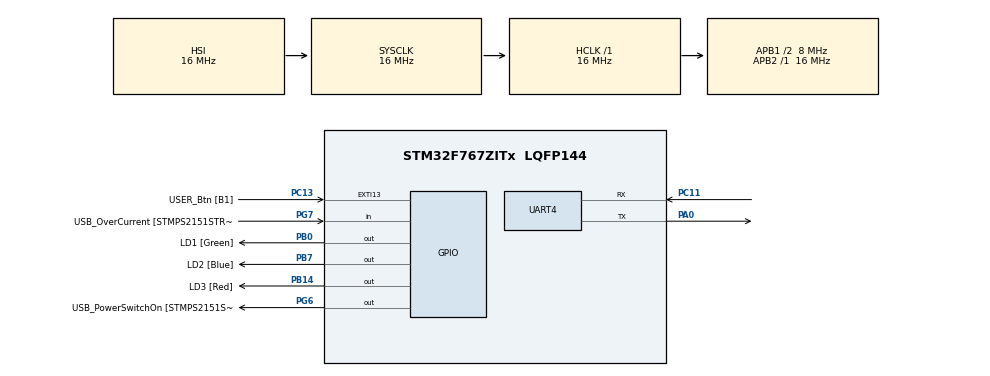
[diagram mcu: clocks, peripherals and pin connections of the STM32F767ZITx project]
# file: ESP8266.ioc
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Mcu.Family=STM32F7
RCC.CortexFreq_Value=16000000
PG6.Signal=GPIO_Output
PB14.GPIO_Label=LD3 [Red]
PG6.GPIO_Label=USB_PowerSwitchOn [STMPS2151STR_EN]
PA14.GPIO_Label=TCK
RCC.SYSCLKSourceVirtual=RCC_SYSCLKSOURCE_PLLCLK
PA0/WKUP.Signal=UART4_TX
PB0.GPIO_Label=LD1 [Green]
PC13.GPIO_Label=USER_Btn [B1]
PB13.GPIO_Label=RMII_TXD1 [LAN8742A-CZ-TR_TXD1]
PB13.Signal=ETH_TXD1
PG13.Signal=ETH_TXD0
PG11.Signal=ETH_TX_EN
ProjectManager.StackSize=0x400
PA12.Signal=USB_OTG_FS_DP
RCC.HCLKFreq_Value=16000000
RCC.APB2TimFreq_Value=16000000
PH1/OSC_OUT.Signal=RCC_OSC_OUT
PD8.Signal=USART3_TX
RCC.AHBFreq_Value=16000000
RCC.HSE_VALUE=16000000
TIM14.Period=20001
RCC.PLLMUL=RCC_PLL_MUL9
PC4.GPIO_Label=RMII_RXD0 [LAN8742A-CZ-TR_RXD0]
PA10.GPIO_Label=USB_ID
PB7.Signal=GPIO_Output
PA8.Signal=USB_OTG_FS_SOF
PB7.GPIO_Label=LD2 [Blue]
Mcu.Package=LQFP144
PC14/OSC32_IN.Signal=RCC_OSC32_IN
PA2.GPIO_Label=RMII_MDIO [LAN8742A-CZ-TR_MDIO]
PA10.Signal=USB_OTG_FS_ID
PC11.Mode=Asynchronous
RCC.APB1TimFreq_Value=16000000
PG11.GPIO_Label=RMII_TX_EN [LAN8742A-CZ-TR_TXEN]
PC5.Signal=ETH_RXD1
VP_TIM14_VS_ClockSourceINT.Mode=Enable_Timer
NVIC.UART4_IRQn=true\:0\:0\:false\:false\:true\:true\:true
PB3.GPIO_Label=SW0
PG7.Signal=GPIO_Input
PD9.GPIO_Label=STLK_TX [STM32F103CBT6_PA2]
PC13.Signal=GPXTI13
PA9.GPIO_Label=USB_VBUS
PC11.Signal=UART4_RX
PC4.Signal=ETH_RXD0
PA11.GPIO_Label=USB_DM
PD9.Signal=USART3_RX
RCC.APB1CLKDivider=RCC_HCLK_DIV2
PG13.GPIO_Label=RMII_TXD0 [LAN8742A-CZ-TR_TXD0]
PA12.GPIO_Label=USB_DP
PD8.GPIO_Label=STLK_RX [STM32F103CBT6_PA3]
PA13.Signal=SYS_JTMS-SWDIO
PA8.GPIO_Label=USB_SOF [TP1]
ProjectManager.TargetToolchain=STM32CubeIDE
PA9.Signal=USB_OTG_FS_VBUS
RCC.USBFreq_Value=96000000
RCC.LSE_VALUE=32768
PA1.Signal=ETH_REF_CLK
PA0/WKUP.Mode=Asynchronous
PB14.Signal=GPIO_Output
board=NUCLEO-F767ZI
RCC.VCOOutputFreq_Value=192000000
PH0/OSC_IN.Signal=RCC_OSC_IN
RCC.APB2Freq_Value=16000000
RCC.PRESCALERUSB=RCC_USBCLKSOURCE_PLL_DIV1_5
PG7.GPIO_Label=USB_OverCurrent [STMPS2151STR_FAULT]
PA1.GPIO_Label=RMII_REF_CLK [LAN8742A-CZ-TR_REFCLK0]
PC1.GPIO_Label=RMII_MDC [LAN8742A-CZ-TR_MDC]
Mcu.Name=STM32F767ZITx
TIM14.Prescaler=1601-1
PA2.Signal=ETH_MDIO
PA13.GPIO_Label=TMS
RCC.48MHZClocksFreq_Value=24000000
PB3.Signal=SYS_JTDO-SWO
RCC.SYSCLKFreq_VALUE=16000000
PA7.GPIO_Label=RMII_CRS_DV [LAN8742A-CZ-TR_CRS_DV]
PC5.GPIO_Label=RMII_RXD1 [LAN8742A-CZ-TR_RXD1]
PA11.Signal=USB_OTG_FS_DM
PA14.Signal=SYS_JTCK-SWCLK
ProjectManager.HeapSize=0x200
RCC.HSI_VALUE=16000000
PH0/OSC_IN.GPIO_Label=MCO [STM32F103CBT6_PA8]
NVIC.PriorityGroup=NVIC_PRIORITYGROUP_4
PC15/OSC32_OUT.Signal=RCC_OSC32_OUT
RCC.APB1Freq_Value=8000000
PB0.Signal=GPIO_Output
PC1.Signal=ETH_MDC
PA7.Signal=ETH_CRS_DV

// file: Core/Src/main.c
/* USER CODE BEGIN Header */
/**
  ******************************************************************************
  * @file           : main.c
  * @brief          : Main program body
  ******************************************************************************
  * @attention
  *
  * <h2><center>&copy; Copyright (c) 2021 STMicroelectronics.
  * All rights reserved.</center></h2>
  *
  * This software component is licensed by ST under BSD 3-Clause license,
  * the "License"; You may not use this file except in compliance with the
  * License. You may obtain a copy of the License at:
  *                        opensource.org/licenses/BSD-3-Clause
  *
  ******************************************************************************
  */
/* USER CODE END Header */
#include "main.h"

/* USER CODE BEGIN Includes */
#include "ESP8266.h"
/* USER CODE END Includes */

TIM_HandleTypeDef htim14;

UART_HandleTypeDef huart4;

/* USER CODE BEGIN PV */
char SSID[20] = "\"SSID\"";
char password[20] = "\"Password\"";
char IP[20] = "\"184.106.153.149\"";
char write_API_key[17] = "ZU5WVONXNXJPLRUX";
const int port = 80;

double sensor_output = 60.23;
bool OK_received_flag;

struct ESP8266 ESP = {SSID, password, IP, port, write_API_key};

/* USER CODE END PV */

void SystemClock_Config(void);
static void MX_GPIO_Init(void);
static void MX_UART4_Init(void);
static void MX_TIM14_Init(void);

int main(void)
{

  /* MCU Configuration--------------------------------------------------------*/

  /* Reset of all peripherals, Initializes the Flash interface and the Systick. */
  HAL_Init();

  /* Configure the system clock */
  SystemClock_Config();

  /* Initialize all configured peripherals */
  MX_GPIO_Init();
  MX_UART4_Init();
  MX_TIM14_Init();
  /* USER CODE BEGIN 2 */

  OK_received_flag = ESP8266_Test();
  ESP8266_WiFiSetup(ESP.SSID, ESP.password);
  TCP_Connect(ESP.IP, ESP.port);
  TS_Write(ESP.write_API_key, sensor_output);
  /* USER CODE END 2 */

  /* Infinite loop */
  while (1)
  {

  }
}

void SystemClock_Config(void)
{
  RCC_OscInitTypeDef RCC_OscInitStruct = {0};
  RCC_ClkInitTypeDef RCC_ClkInitStruct = {0};
  RCC_PeriphCLKInitTypeDef PeriphClkInitStruct = {0};

  /** Configure the main internal regulator output voltage
  */
  __HAL_RCC_PWR_CLK_ENABLE();
  __HAL_PWR_VOLTAGESCALING_CONFIG(PWR_REGULATOR_VOLTAGE_SCALE3);
  /** Initializes the RCC Oscillators according to the specified parameters
  * in the RCC_OscInitTypeDef structure.
  */
  RCC_OscInitStruct.OscillatorType = RCC_OSCILLATORTYPE_HSI;
  RCC_OscInitStruct.HSIState = RCC_HSI_ON;
  RCC_OscInitStruct.HSICalibrationValue = RCC_HSICALIBRATION_DEFAULT;
  RCC_OscInitStruct.PLL.PLLState = RCC_PLL_NONE;
  if (HAL_RCC_OscConfig(&RCC_OscInitStruct) != HAL_OK)
  {
    Error_Handler();
  }
  /** Initializes the CPU, AHB and APB buses clocks
  */
  RCC_ClkInitStruct.ClockType = RCC_CLOCKTYPE_HCLK|RCC_CLOCKTYPE_SYSCLK
                              |RCC_CLOCKTYPE_PCLK1|RCC_CLOCKTYPE_PCLK2;
  RCC_ClkInitStruct.SYSCLKSource = RCC_SYSCLKSOURCE_HSI;
  RCC_ClkInitStruct.AHBCLKDivider = RCC_SYSCLK_DIV1;
  RCC_ClkInitStruct.APB1CLKDivider = RCC_HCLK_DIV2;
  RCC_ClkInitStruct.APB2CLKDivider = RCC_HCLK_DIV1;

  if (HAL_RCC_ClockConfig(&RCC_ClkInitStruct, FLASH_LATENCY_0) != HAL_OK)
  {
    Error_Handler();
  }
  PeriphClkInitStruct.PeriphClockSelection = RCC_PERIPHCLK_UART4;
  PeriphClkInitStruct.Uart4ClockSelection = RCC_UART4CLKSOURCE_PCLK1;
  if (HAL_RCCEx_PeriphCLKConfig(&PeriphClkInitStruct) != HAL_OK)
  {
    Error_Handler();
  }
}

static void MX_TIM14_Init(void)
{

  htim14.Instance = TIM14;
  htim14.Init.Prescaler = 1601-1;
  htim14.Init.CounterMode = TIM_COUNTERMODE_UP;
  htim14.Init.Period = 20001;
  htim14.Init.ClockDivision = TIM_CLOCKDIVISION_DIV1;
  htim14.Init.AutoReloadPreload = TIM_AUTORELOAD_PRELOAD_DISABLE;
  if (HAL_TIM_Base_Init(&htim14) != HAL_OK)
  {
    Error_Handler();
  }

}

static void MX_UART4_Init(void)
{

  huart4.Instance = UART4;
  huart4.Init.BaudRate = 115200;
  huart4.Init.WordLength = UART_WORDLENGTH_8B;
  huart4.Init.StopBits = UART_STOPBITS_1;
  huart4.Init.Parity = UART_PARITY_NONE;
  huart4.Init.Mode = UART_MODE_TX_RX;
  huart4.Init.HwFlowCtl = UART_HWCONTROL_NONE;
  huart4.Init.OverSampling = UART_OVERSAMPLING_16;
  huart4.Init.OneBitSampling = UART_ONE_BIT_SAMPLE_DISABLE;
  huart4.AdvancedInit.AdvFeatureInit = UART_ADVFEATURE_NO_INIT;
  if (HAL_UART_Init(&huart4) != HAL_OK)
  {
    Error_Handler();
  }

}

static void MX_GPIO_Init(void)
{
  GPIO_InitTypeDef GPIO_InitStruct = {0};

  /* GPIO Ports Clock Enable */
  __HAL_RCC_GPIOC_CLK_ENABLE();
  __HAL_RCC_GPIOH_CLK_ENABLE();
  __HAL_RCC_GPIOA_CLK_ENABLE();
  __HAL_RCC_GPIOB_CLK_ENABLE();
  __HAL_RCC_GPIOD_CLK_ENABLE();
  __HAL_RCC_GPIOG_CLK_ENABLE();

  /*Configure GPIO pin Output Level */
  HAL_GPIO_WritePin(GPIOB, LD1_Pin|LD3_Pin|LD2_Pin, GPIO_PIN_RESET);

  /*Configure GPIO pin Output Level */
  HAL_GPIO_WritePin(USB_PowerSwitchOn_GPIO_Port, USB_PowerSwitchOn_Pin, GPIO_PIN_RESET);

  /*Configure GPIO pin : USER_Btn_Pin */
  GPIO_InitStruct.Pin = USER_Btn_Pin;
  GPIO_InitStruct.Mode = GPIO_MODE_IT_RISING;
  GPIO_InitStruct.Pull = GPIO_NOPULL;
  HAL_GPIO_Init(USER_Btn_GPIO_Port, &GPIO_InitStruct);

  /*Configure GPIO pins : RMII_MDC_Pin RMII_RXD0_Pin RMII_RXD1_Pin */
  GPIO_InitStruct.Pin = RMII_MDC_Pin|RMII_RXD0_Pin|RMII_RXD1_Pin;
  GPIO_InitStruct.Mode = GPIO_MODE_AF_PP;
  GPIO_InitStruct.Pull = GPIO_NOPULL;
  GPIO_InitStruct.Speed = GPIO_SPEED_FREQ_VERY_HIGH;
  GPIO_InitStruct.Alternate = GPIO_AF11_ETH;
  HAL_GPIO_Init(GPIOC, &GPIO_InitStruct);

  /*Configure GPIO pins : RMII_REF_CLK_Pin RMII_MDIO_Pin RMII_CRS_DV_Pin */
  GPIO_InitStruct.Pin = RMII_REF_CLK_Pin|RMII_MDIO_Pin|RMII_CRS_DV_Pin;
  GPIO_InitStruct.Mode = GPIO_MODE_AF_PP;
  GPIO_InitStruct.Pull = GPIO_NOPULL;
  GPIO_InitStruct.Speed = GPIO_SPEED_FREQ_VERY_HIGH;
  GPIO_InitStruct.Alternate = GPIO_AF11_ETH;
  HAL_GPIO_Init(GPIOA, &GPIO_InitStruct);

  /*Configure GPIO pins : LD1_Pin LD3_Pin LD2_Pin */
  GPIO_InitStruct.Pin = LD1_Pin|LD3_Pin|LD2_Pin;
  GPIO_InitStruct.Mode = GPIO_MODE_OUTPUT_PP;
  GPIO_InitStruct.Pull = GPIO_NOPULL;
  GPIO_InitStruct.Speed = GPIO_SPEED_FREQ_LOW;
  HAL_GPIO_Init(GPIOB, &GPIO_InitStruct);

  /*Configure GPIO pin : RMII_TXD1_Pin */
  GPIO_InitStruct.Pin = RMII_TXD1_Pin;
  GPIO_InitStruct.Mode = GPIO_MODE_AF_PP;
  GPIO_InitStruct.Pull = GPIO_NOPULL;
  GPIO_InitStruct.Speed = GPIO_SPEED_FREQ_VERY_HIGH;
  GPIO_InitStruct.Alternate = GPIO_AF11_ETH;
  HAL_GPIO_Init(RMII_TXD1_GPIO_Port, &GPIO_InitStruct);

  /*Configure GPIO pins : STLK_RX_Pin STLK_TX_Pin */
  GPIO_InitStruct.Pin = STLK_RX_Pin|STLK_TX_Pin;
  GPIO_InitStruct.Mode = GPIO_MODE_AF_PP;
  GPIO_InitStruct.Pull = GPIO_NOPULL;
  GPIO_InitStruct.Speed = GPIO_SPEED_FREQ_VERY_HIGH;
  GPIO_InitStruct.Alternate = GPIO_AF7_USART3;
  HAL_GPIO_Init(GPIOD, &GPIO_InitStruct);

  /*Configure GPIO pin : USB_PowerSwitchOn_Pin */
  GPIO_InitStruct.Pin = USB_PowerSwitchOn_Pin;
  GPIO_InitStruct.Mode = GPIO_MODE_OUTPUT_PP;
  GPIO_InitStruct.Pull = GPIO_NOPULL;
  GPIO_InitStruct.Speed = GPIO_SPEED_FREQ_LOW;
  HAL_GPIO_Init(USB_PowerSwitchOn_GPIO_Port, &GPIO_InitStruct);

  /*Configure GPIO pin : USB_OverCurrent_Pin */
  GPIO_InitStruct.Pin = USB_OverCurrent_Pin;
  GPIO_InitStruct.Mode = GPIO_MODE_INPUT;
  GPIO_InitStruct.Pull = GPIO_NOPULL;
  HAL_GPIO_Init(USB_OverCurrent_GPIO_Port, &GPIO_InitStruct);

  /*Configure GPIO pins : USB_SOF_Pin USB_ID_Pin USB_DM_Pin USB_DP_Pin */
  GPIO_InitStruct.Pin = USB_SOF_Pin|USB_ID_Pin|USB_DM_Pin|USB_DP_Pin;
  GPIO_InitStruct.Mode = GPIO_MODE_AF_PP;
  GPIO_InitStruct.Pull = GPIO_NOPULL;
  GPIO_InitStruct.Speed = GPIO_SPEED_FREQ_VERY_HIGH;
  GPIO_InitStruct.Alternate = GPIO_AF10_OTG_FS;
  HAL_GPIO_Init(GPIOA, &GPIO_InitStruct);

  /*Configure GPIO pin : USB_VBUS_Pin */
  GPIO_InitStruct.Pin = USB_VBUS_Pin;
  GPIO_InitStruct.Mode = GPIO_MODE_INPUT;
  GPIO_InitStruct.Pull = GPIO_NOPULL;
  HAL_GPIO_Init(USB_VBUS_GPIO_Port, &GPIO_InitStruct);

  /*Configure GPIO pins : RMII_TX_EN_Pin RMII_TXD0_Pin */
  GPIO_InitStruct.Pin = RMII_TX_EN_Pin|RMII_TXD0_Pin;
  GPIO_InitStruct.Mode = GPIO_MODE_AF_PP;
  GPIO_InitStruct.Pull = GPIO_NOPULL;
  GPIO_InitStruct.Speed = GPIO_SPEED_FREQ_VERY_HIGH;
  GPIO_InitStruct.Alternate = GPIO_AF11_ETH;
  HAL_GPIO_Init(GPIOG, &GPIO_InitStruct);

}

/* USER CODE BEGIN 4 */
void HAL_UART_RxCpltCallback(UART_HandleTypeDef *huart)
{

}

/* USER CODE END 4 */

void Error_Handler(void)
{
  __disable_irq();
  while (1)
  {
  }
}

/************************ (C) COPYRIGHT STMicroelectronics *****END OF FILE****/
